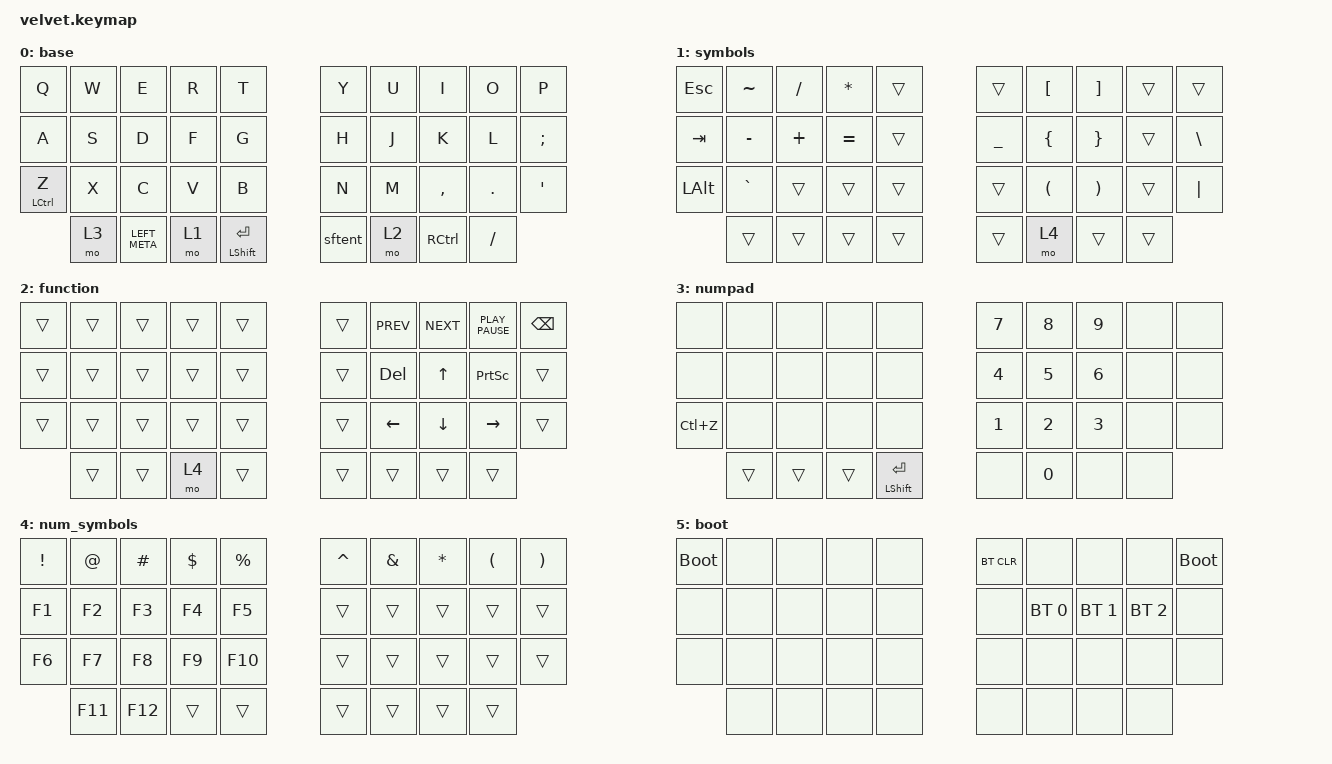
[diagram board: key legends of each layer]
#include <behaviors.dtsi>
#include <dt-bindings/zmk/bt.h>
#include <dt-bindings/zmk/keys.h>

/ {
    combos {
        compatible = "zmk,combos";
        boot {
            bindings = <&mo 5>;
            key-positions = <24 25 32 35>;
        };
    };

    behaviors {
        sftent: sftent {
            compatible = "zmk,behavior-mod-morph";
            label = "sftent";
            #binding-cells = <0>;
            bindings = <&kp SPACE>, <&kp ENTER>;
            mods = <(MOD_LSFT)>;
            keep-mods = <(MOD_LSFT)>;
        };
    };

    keymap {
        compatible = "zmk,keymap";

        // 0
        base {
            bindings = <
                &kp Q           &kp W       &kp E           &kp R       &kp T                                   &kp Y                   &kp U                   &kp I               &kp O               &kp P
                &kp A           &kp S       &kp D           &kp F       &kp G                                   &kp H                   &kp J                   &kp K               &kp L               &kp SEMI
                &mt LCTRL Z     &kp X       &kp C           &kp V       &kp B                                   &kp N                   &kp M                   &kp COMMA           &kp DOT             &kp APOS
                                &mo 3       &kp LEFT_META   &mo 1       &mt LEFT_SHIFT ENTER                    &sftent                 &mo 2                   &kp RCTRL           &kp SLASH
            >;
        };

        // 1
        symbols {
            bindings = <
                &kp ESCAPE      &kp TILDE   &kp SLASH       &kp ASTERISK&trans                                  &trans                  &kp LBKT                &kp RBKT            &trans              &trans
                &kp TAB         &kp MINUS   &kp PLUS        &kp EQUAL   &trans                                  &kp UNDERSCORE          &kp LBRC                &kp RBRC            &trans              &kp BSLH
                &kp LEFT_ALT    &kp GRAVE   &trans          &trans      &trans                                  &trans                  &kp LPAR                &kp RPAR            &trans              &kp PIPE
                                &trans      &trans          &trans      &trans                                  &trans                  &mo 4                   &trans              &trans
            >;
        };

        // 2
        function {
            bindings = <
                &trans          &trans      &trans          &trans      &trans                                  &trans                  &kp K_PREV              &kp K_NEXT          &kp K_PLAY_PAUSE    &kp BACKSPACE
                &trans          &trans      &trans          &trans      &trans                                  &trans                  &kp DELETE              &kp UP              &kp PRINTSCREEN     &trans
                &trans          &trans      &trans          &trans      &trans                                  &trans                  &kp LEFT                &kp DOWN            &kp RIGHT           &trans
                                &trans      &trans          &mo 4       &trans                                  &trans                  &trans                  &trans              &trans
            >;
        };

        // 3
        numpad {
            bindings = <
                &none           &none       &none           &none       &none                                   &kp N7                  &kp N8                  &kp N9              &none               &none
                &none           &none       &none           &none       &none                                   &kp N4                  &kp N5                  &kp N6              &none               &none
                &kp LC(Z)       &none       &none           &none       &none                                   &kp N1                  &kp N2                  &kp N3              &none               &none
                                &trans      &trans          &trans      &mt LEFT_SHIFT ENTER                    &none                   &kp N0                  &none               &none
            >;
        };

        // 4
        num_symbols {
            bindings = <
                &kp EXCLAMATION &kp AT_SIGN &kp POUND       &kp DOLLAR  &kp PERCENT                             &kp CARET               &kp AMPERSAND           &kp ASTERISK        &kp LPAR            &kp RPAR
                &kp F1          &kp F2      &kp F3          &kp F4      &kp F5                                  &trans                  &trans                  &trans              &trans              &trans
                &kp F6          &kp F7      &kp F8          &kp F9      &kp F10                                 &trans                  &trans                  &trans              &trans              &trans
                                &kp F11     &kp F12         &trans      &trans                                  &trans                  &trans                  &trans              &trans
            >;
        };

        // 5
        boot {
            bindings = <
                &bootloader     &none       &none           &none       &none                                   &bt BT_CLR              &none                   &none               &none               &bootloader
                &none           &none       &none           &none       &none                                   &none                   &bt BT_SEL 0            &bt BT_SEL 1        &bt BT_SEL 2        &none
                &none           &none       &none           &none       &none                                   &none                   &none                   &none               &none               &none
                                &none       &none           &none       &none                                   &none                   &none                   &none               &none
            >;
        };
    };
};
